VERSION ""

NS_ :

BS_:

BU_: XXX

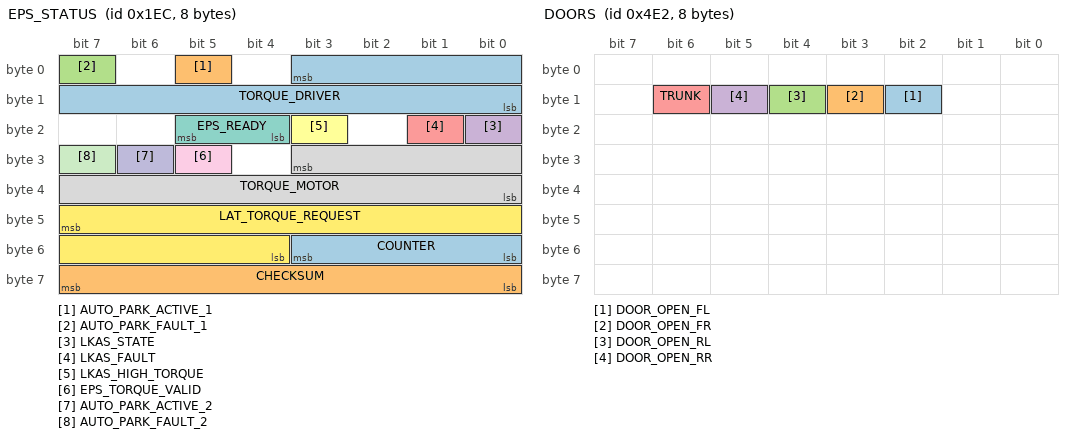
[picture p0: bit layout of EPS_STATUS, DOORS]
BO_ 492 EPS_STATUS: 8 XXX
 SG_ TORQUE_DRIVER : 3|12@0+ (1,-1024) [0|2048] "Nm" XXX
 SG_ AUTO_PARK_ACTIVE_1 : 5|1@0+ (1,0) [0|1] "" XXX
 SG_ AUTO_PARK_FAULT_1 : 7|1@0+ (1,0) [0|1] "" XXX
 SG_ LKAS_STATE : 16|1@0+ (1,0) [0|1] "" XXX
 SG_ LKAS_FAULT : 17|1@0+ (1,0) [0|1] "" XXX
 SG_ LKAS_HIGH_TORQUE : 19|1@0+ (1,0) [0|1] "" XXX
 SG_ EPS_READY : 21|2@0+ (1,0) [0|3] "" XXX
 SG_ TORQUE_MOTOR : 27|12@0+ (1,-2048) [0|1] "" XXX
 SG_ EPS_TORQUE_VALID : 29|1@0+ (1,0) [0|1] "" XXX
 SG_ AUTO_PARK_ACTIVE_2 : 30|1@0+ (1,0) [0|1] "" XXX
 SG_ AUTO_PARK_FAULT_2 : 31|1@0+ (1,0) [0|1] "" XXX
 SG_ LAT_TORQUE_REQUEST : 47|12@0+ (1,-2048) [0|4095] "" XXX
 SG_ COUNTER : 51|4@0+ (1,0) [0|15] "" XXX
 SG_ CHECKSUM : 63|8@0+ (1,0) [0|255] "" XXX

BO_ 1250 DOORS: 8 XXX
 SG_ DOOR_OPEN_FL : 10|1@0+ (1,0) [0|1] "" XXX
 SG_ DOOR_OPEN_FR : 11|1@0+ (1,0) [0|1] "" XXX
 SG_ DOOR_OPEN_RL : 12|1@0+ (1,0) [0|1] "" XXX
 SG_ DOOR_OPEN_RR : 13|1@0+ (1,0) [0|1] "" XXX
 SG_ TRUNK : 14|1@0+ (1,0) [0|1] "" XXX

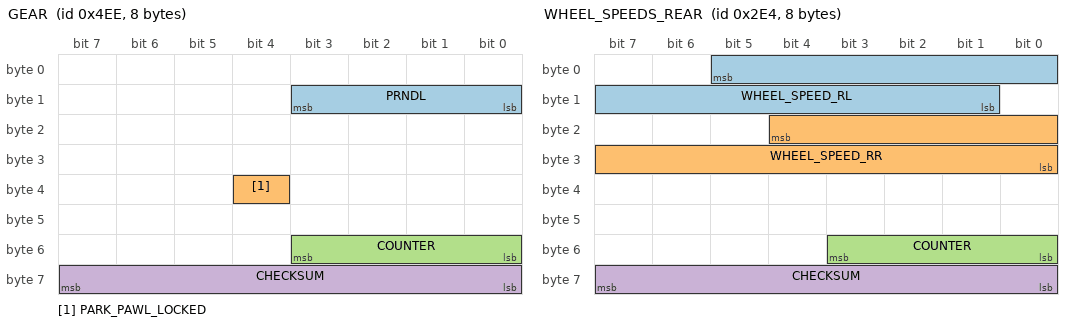
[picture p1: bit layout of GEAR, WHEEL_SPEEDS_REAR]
BO_ 1262 GEAR: 8 XXX
 SG_ PRNDL : 11|4@0+ (1,0) [0|15] "" XXX
 SG_ PARK_PAWL_LOCKED : 36|1@0+ (1,0) [0|1] "" XXX
 SG_ COUNTER : 51|4@0+ (1,0) [0|15] "" XXX
 SG_ CHECKSUM : 63|8@0+ (1,0) [0|255] "" XXX

BO_ 875 SEATBELT_STATUS: 8 XXX
 SG_ SEATBELT_DRIVER_UNLATCHED : 16|1@0+ (1,0) [0|1] "" XXX

BO_ 1264 STEERING_LEVERS: 7 XXX
 SG_ TURN_SIGNALS : 3|4@0+ (1,0) [0|15] "" XXX
 SG_ HIGH_BEAM_FLASH : 15|1@0+ (1,0) [0|1] "" XXX

BO_ 480 TRACTION_BUTTON: 8 XXX
 SG_ TRACTION_OFF : 3|1@0+ (1,0) [0|1] "" XXX

BO_ 740 WHEEL_SPEEDS_REAR: 8 XXX
 SG_ WHEEL_SPEED_RL : 5|13@0+ (0.0087,0) [0|1] "" XXX
 SG_ WHEEL_SPEED_RR : 20|13@0+ (0.0087,0) [0|1] "" XXX
 SG_ COUNTER : 51|4@0+ (1,0) [0|1] "" XXX
 SG_ CHECKSUM : 63|8@0+ (1,0) [0|1] "" XXX

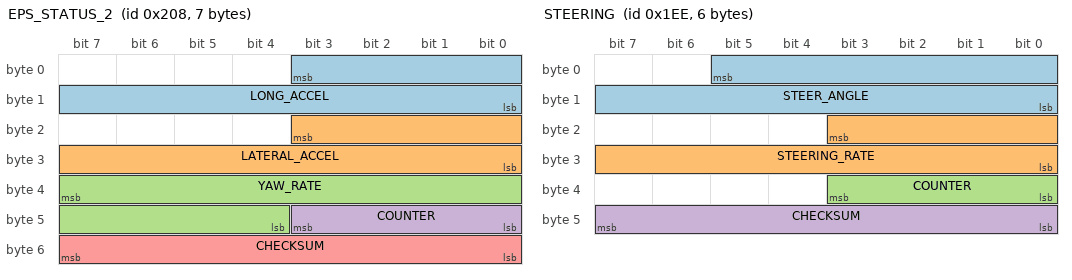
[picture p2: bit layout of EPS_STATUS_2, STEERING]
BO_ 520 EPS_STATUS_2: 7 XXX
 SG_ LONG_ACCEL : 3|12@0+ (0.00981,-20.09) [-20.09|20.08] "m/s2" XXX
 SG_ LATERAL_ACCEL : 19|12@0+ (0.00981,-20.09) [-20.09|20.08] "m/s2" XXX
 SG_ YAW_RATE : 39|12@0+ (0.0018,-3.686) [-3.686|3.685] "rad/s" XXX
 SG_ COUNTER : 43|4@0+ (1,0) [0|15] "" XXX
 SG_ CHECKSUM : 55|8@0+ (1,0) [0|255] "" XXX

BO_ 494 STEERING: 6 XXX
 SG_ STEER_ANGLE : 5|14@0+ (0.1,-720) [0|1] "deg" XXX
 SG_ STEERING_RATE : 19|12@0+ (1,-2000) [0|1] "" XXX
 SG_ COUNTER : 35|4@0+ (1,0) [0|15] "" XXX
 SG_ CHECKSUM : 47|8@0+ (1,0) [0|255] "" XXX

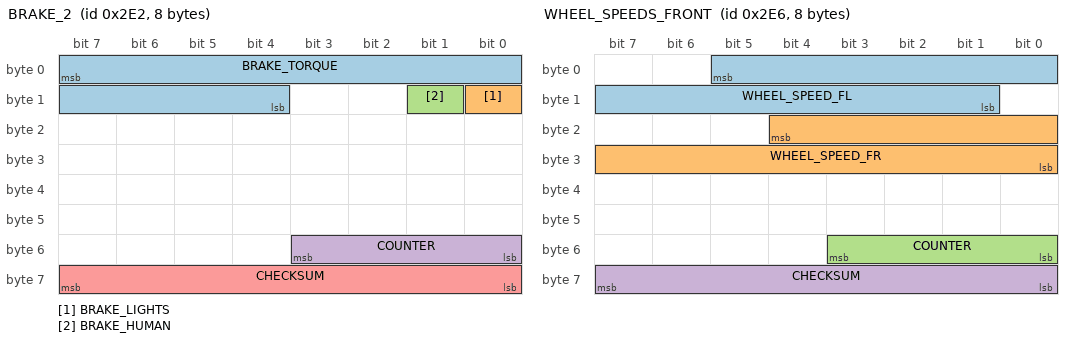
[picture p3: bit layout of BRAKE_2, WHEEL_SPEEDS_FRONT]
BO_ 738 BRAKE_2: 8 XXX
 SG_ BRAKE_TORQUE : 7|12@0+ (1,0) [0|15] "" XXX
 SG_ BRAKE_LIGHTS : 8|1@0+ (1,0) [0|1] "" XXX
 SG_ BRAKE_HUMAN : 9|1@0+ (1,0) [0|1] "" XXX
 SG_ COUNTER : 51|4@0+ (1,0) [0|1] "" XXX
 SG_ CHECKSUM : 63|8@0+ (1,0) [0|1] "" XXX

BO_ 742 WHEEL_SPEEDS_FRONT: 8 XXX
 SG_ WHEEL_SPEED_FL : 5|13@0+ (0.0087,0) [0|1] "" XXX
 SG_ WHEEL_SPEED_FR : 20|13@0+ (0.0087,0) [0|1] "" XXX
 SG_ COUNTER : 51|4@0+ (1,0) [0|1] "" XXX
 SG_ CHECKSUM : 63|8@0+ (1,0) [0|1] "" XXX

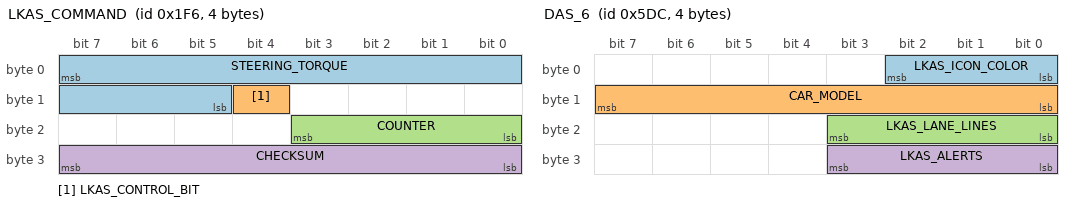
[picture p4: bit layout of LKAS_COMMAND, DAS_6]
BO_ 502 LKAS_COMMAND: 4 XXX
 SG_ STEERING_TORQUE : 7|11@0+ (1,-1024) [0|4087] "" XXX
 SG_ LKAS_CONTROL_BIT : 12|1@0+ (1,0) [0|1] "" XXX
 SG_ COUNTER : 19|4@0+ (1,0) [0|1] "" XXX
 SG_ CHECKSUM : 31|8@0+ (1,0) [0|1] "" XXX

BO_ 1498 LKAS_1: 2 XXX

BO_ 1500 DAS_6: 4 XXX
 SG_ LKAS_ICON_COLOR : 2|3@0+ (1,0) [0|7] "" XXX
 SG_ CAR_MODEL : 15|8@0+ (1,0) [0|255] "" XXX
 SG_ LKAS_LANE_LINES : 19|4@0+ (1,0) [0|15] "" XXX
 SG_ LKAS_ALERTS : 27|4@0+ (1,0) [0|1] "" XXX

BO_ 1508 LKAS_HEARTBIT: 8 XXX
 SG_ LKAS_STATUS_OK : 28|1@0+ (1,0) [0|1] "" XXX

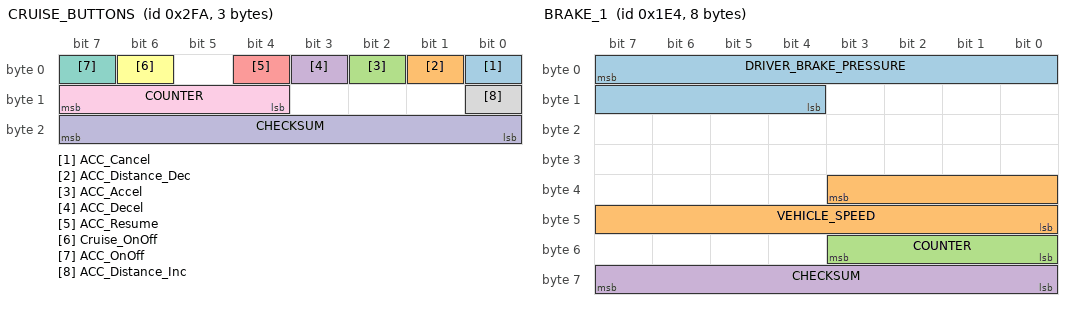
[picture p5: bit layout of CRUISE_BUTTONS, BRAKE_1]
BO_ 762 CRUISE_BUTTONS: 3 XXX
 SG_ ACC_Cancel : 0|1@0+ (1,0) [0|1] "" XXX
 SG_ ACC_Distance_Dec : 1|1@0+ (1,0) [0|1] "" XXX
 SG_ ACC_Accel : 2|1@0+ (1,0) [0|1] "" XXX
 SG_ ACC_Decel : 3|1@0+ (1,0) [0|1] "" XXX
 SG_ ACC_Resume : 4|1@0+ (1,0) [0|1] "" XXX
 SG_ Cruise_OnOff : 6|1@0+ (1,0) [0|1] "" XXX
 SG_ ACC_OnOff : 7|1@0+ (1,0) [0|1] "" XXX
 SG_ ACC_Distance_Inc : 8|1@0+ (1,0) [0|1] "" XXX
 SG_ COUNTER : 15|4@0+ (1,0) [0|1] "" XXX
 SG_ CHECKSUM : 23|8@0+ (1,0) [0|1] "" XXX

BO_ 484 BRAKE_1: 8 XXX
 SG_ DRIVER_BRAKE_PRESSURE : 7|12@0+ (1,0) [0|1] "" XXX
 SG_ VEHICLE_SPEED : 35|12@0+ (0.0174,0) [0|4095] "m/s" XXX
 SG_ COUNTER : 51|4@0+ (1,0) [0|1] "" XXX
 SG_ CHECKSUM : 63|8@0+ (1,0) [0|1] "" XXX

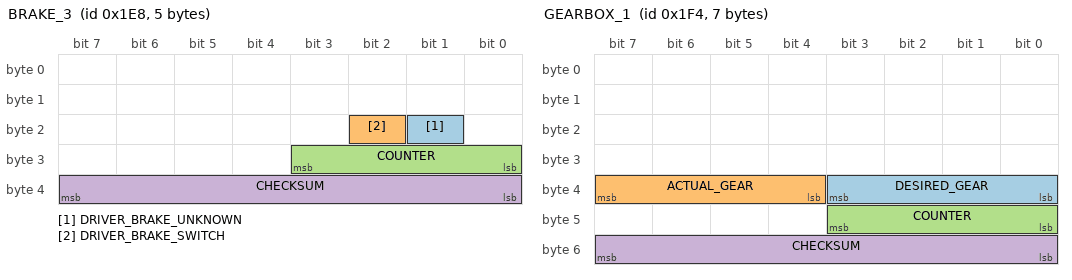
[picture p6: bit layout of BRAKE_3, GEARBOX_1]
BO_ 488 BRAKE_3: 5 XXX
 SG_ DRIVER_BRAKE_UNKNOWN : 17|1@0+ (1,0) [0|1] "" XXX
 SG_ DRIVER_BRAKE_SWITCH : 18|1@0+ (1,0) [0|1] "" XXX
 SG_ COUNTER : 27|4@0+ (1,0) [0|15] "" XXX
 SG_ CHECKSUM : 39|8@0+ (1,0) [0|255] "" XXX

BO_ 500 GEARBOX_1: 7 XXX
 SG_ DESIRED_GEAR : 35|4@0+ (1,0) [0|1] "" XXX
 SG_ ACTUAL_GEAR : 39|4@0+ (1,0) [0|1] "" XXX
 SG_ COUNTER : 43|4@0+ (1,0) [0|1] "" XXX
 SG_ CHECKSUM : 55|8@0+ (1,0) [0|1] "" XXX

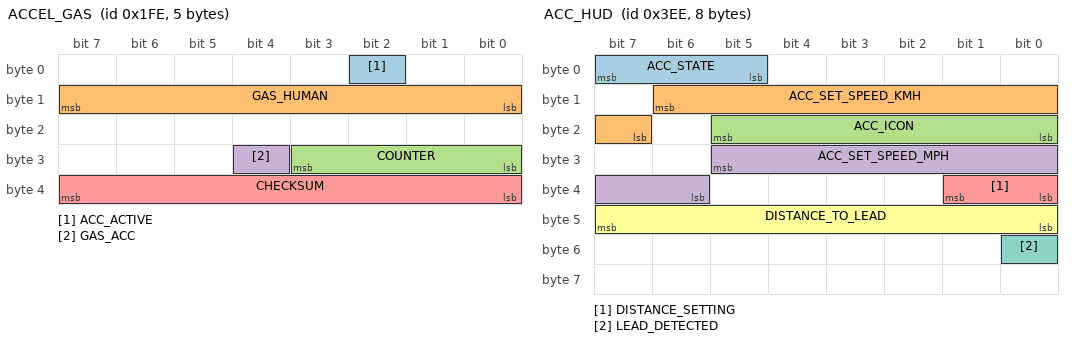
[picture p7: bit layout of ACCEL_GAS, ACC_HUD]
BO_ 510 ACCEL_GAS: 5 XXX
 SG_ ACC_ACTIVE : 2|1@0+ (1,0) [0|1] "" XXX
 SG_ GAS_HUMAN : 15|8@0+ (1,0) [0|1] "" XXX
 SG_ COUNTER : 27|4@0+ (1,0) [0|1] "" XXX
 SG_ GAS_ACC : 28|1@0+ (1,0) [0|1] "" XXX
 SG_ CHECKSUM : 39|8@0+ (1,0) [0|1] "" XXX

BO_ 490 DASHBOARD: 4 XXX
 SG_ ACC_SPEED_CONFIG_KPH : 7|8@0+ (0.1625,0) [0|1] "m/s" XXX

BO_ 1006 ACC_HUD: 8 XXX
 SG_ ACC_STATE : 7|3@0+ (1,0) [0|15] "" XXX
 SG_ ACC_SET_SPEED_KMH : 14|8@0+ (1,0) [0|255] "km/h" XXX
 SG_ ACC_ICON : 21|6@0+ (1,0) [0|63] "" XXX
 SG_ ACC_SET_SPEED_MPH : 29|8@0+ (1,0) [0|255] "mph" XXX
 SG_ DISTANCE_SETTING : 33|2@0+ (1,0) [0|3] "" XXX
 SG_ DISTANCE_TO_LEAD : 47|8@0+ (1,0) [0|255] "m" XXX
 SG_ LEAD_DETECTED : 48|1@0+ (1,0) [0|1] "" XXX

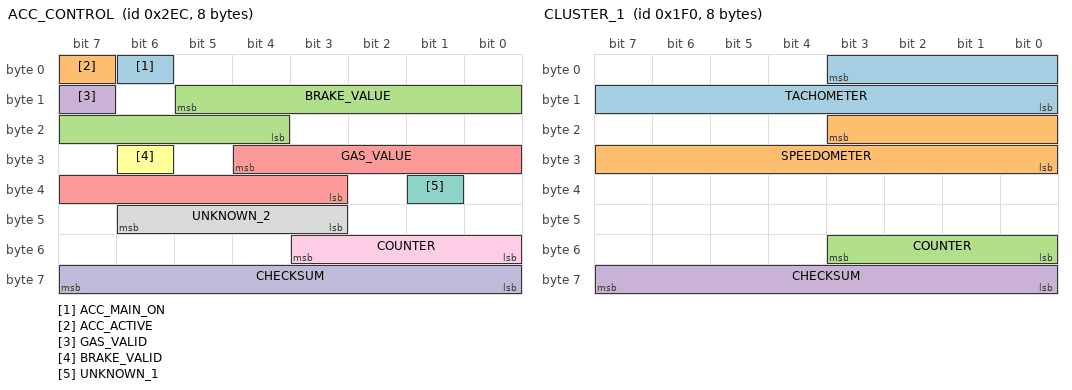
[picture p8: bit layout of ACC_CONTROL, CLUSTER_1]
BO_ 748 ACC_CONTROL: 8 XXX
 SG_ ACC_MAIN_ON : 6|1@0+ (1,0) [0|1] "" XXX
 SG_ ACC_ACTIVE : 7|1@0+ (1,0) [0|1] "" XXX
 SG_ BRAKE_VALUE : 13|10@0+ (1,0) [0|1023] "" XXX
 SG_ GAS_VALID : 15|1@0+ (1,0) [0|1] "" XXX
 SG_ GAS_VALUE : 28|10@0+ (1,0) [0|1023] "" XXX
 SG_ BRAKE_VALID : 30|1@0+ (1,0) [0|1] "" XXX
 SG_ UNKNOWN_1 : 33|1@0+ (1,0) [0|1] "" XXX
 SG_ UNKNOWN_2 : 46|4@0+ (1,0) [0|15] "" XXX
 SG_ COUNTER : 51|4@0+ (1,0) [0|15] "" XXX
 SG_ CHECKSUM : 63|8@0+ (1,0) [0|255] "" XXX

BO_ 496 CLUSTER_1: 8 XXX
 SG_ TACHOMETER : 3|12@0+ (1.024,0) [0|3] "" XXX
 SG_ SPEEDOMETER : 19|12@0+ (0.01065,0) [0|1] "m/s" XXX
 SG_ COUNTER : 51|4@0+ (1,0) [0|1] "" XXX
 SG_ CHECKSUM : 63|8@0+ (1,0) [0|1] "" XXX

BO_ 103596083 BSM_LEFT: 8 XXX
 SG_ LEFT_DETECTED : 21|1@0+ (1,0) [0|1] "" XXX

BO_ 103596084 BSM_RIGHT: 7 XXX
 SG_ RIGHT_DETECTED : 21|1@0+ (1,0) [0|1] "" XXX

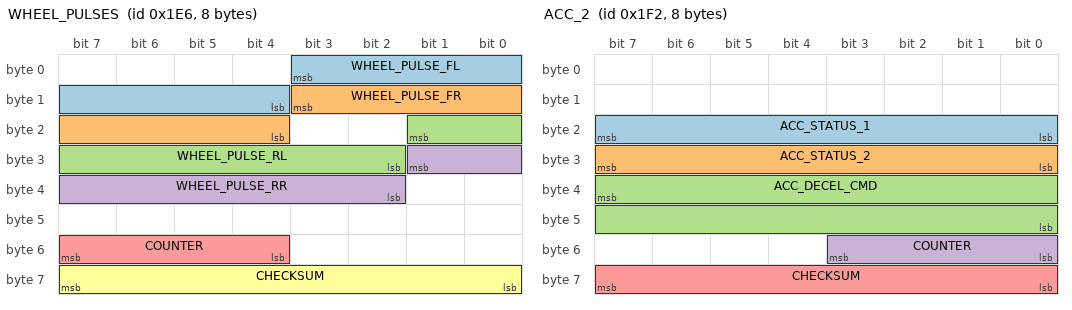
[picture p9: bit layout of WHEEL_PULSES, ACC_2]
BO_ 486 WHEEL_PULSES: 8 XXX
 SG_ WHEEL_PULSE_FL : 3|8@0+ (1,0) [0|255] "" XXX
 SG_ WHEEL_PULSE_FR : 11|8@0+ (1,0) [0|255] "" XXX
 SG_ WHEEL_PULSE_RL : 17|8@0+ (1,0) [0|255] "" XXX
 SG_ WHEEL_PULSE_RR : 25|8@0+ (1,0) [0|255] "" XXX
 SG_ COUNTER : 55|4@0+ (1,0) [0|15] "" XXX
 SG_ CHECKSUM : 63|8@0+ (1,0) [0|255] "" XXX

BO_ 498 ACC_2: 8 XXX
 SG_ ACC_STATUS_1 : 23|8@0+ (1,0) [0|255] "" XXX
 SG_ ACC_STATUS_2 : 31|8@0+ (1,0) [0|255] "" XXX
 SG_ ACC_DECEL_CMD : 39|16@0+ (1,0) [0|65535] "" XXX
 SG_ COUNTER : 51|4@0+ (1,0) [0|15] "" XXX
 SG_ CHECKSUM : 63|8@0+ (1,0) [0|255] "" XXX

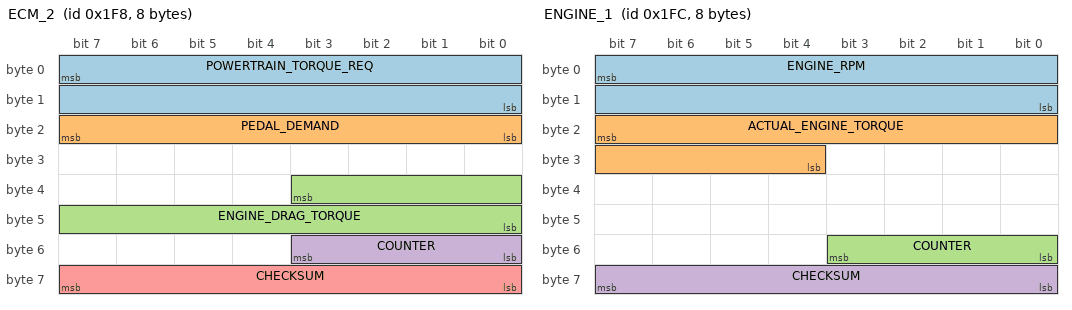
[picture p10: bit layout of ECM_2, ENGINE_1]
BO_ 504 ECM_2: 8 XXX
 SG_ POWERTRAIN_TORQUE_REQ : 7|16@0+ (1,0) [0|65535] "" XXX
 SG_ PEDAL_DEMAND : 23|8@0+ (0.4,0) [0|100] "%" XXX
 SG_ ENGINE_DRAG_TORQUE : 35|12@0+ (1,-1000) [-1000|3095] "Nm" XXX
 SG_ COUNTER : 51|4@0+ (1,0) [0|15] "" XXX
 SG_ CHECKSUM : 63|8@0+ (1,0) [0|255] "" XXX

BO_ 508 ENGINE_1: 8 XXX
 SG_ ENGINE_RPM : 7|16@0+ (1,0) [0|65535] "rpm" XXX
 SG_ ACTUAL_ENGINE_TORQUE : 23|12@0+ (1,-1000) [-1000|3095] "Nm" XXX
 SG_ COUNTER : 51|4@0+ (1,0) [0|15] "" XXX
 SG_ CHECKSUM : 63|8@0+ (1,0) [0|255] "" XXX

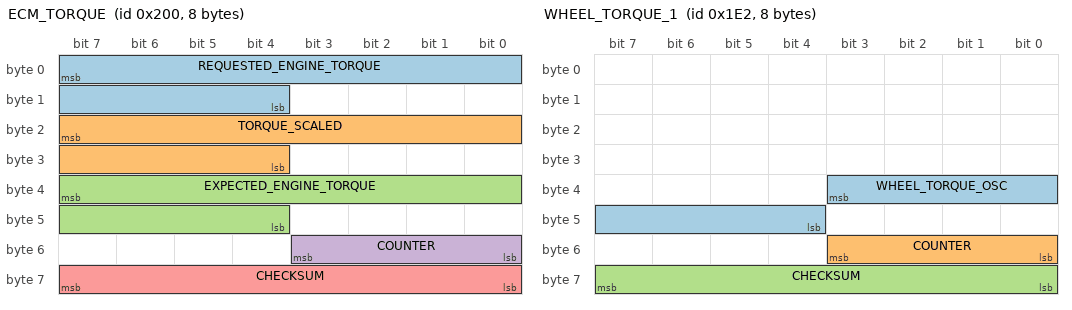
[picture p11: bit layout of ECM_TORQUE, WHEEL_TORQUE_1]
BO_ 512 ECM_TORQUE: 8 XXX
 SG_ REQUESTED_ENGINE_TORQUE : 7|12@0+ (1,-1000) [-1000|3095] "Nm" XXX
 SG_ TORQUE_SCALED : 23|12@0+ (1,-500) [-500|3595] "Nm" XXX
 SG_ EXPECTED_ENGINE_TORQUE : 39|12@0+ (1,-1000) [-1000|3095] "Nm" XXX
 SG_ COUNTER : 51|4@0+ (1,0) [0|15] "" XXX
 SG_ CHECKSUM : 63|8@0+ (1,0) [0|255] "" XXX

BO_ 482 WHEEL_TORQUE_1: 8 XXX
 SG_ WHEEL_TORQUE_OSC : 35|8@0+ (1,0) [0|255] "" XXX
 SG_ COUNTER : 51|4@0+ (1,0) [0|15] "" XXX
 SG_ CHECKSUM : 63|8@0+ (1,0) [0|255] "" XXX

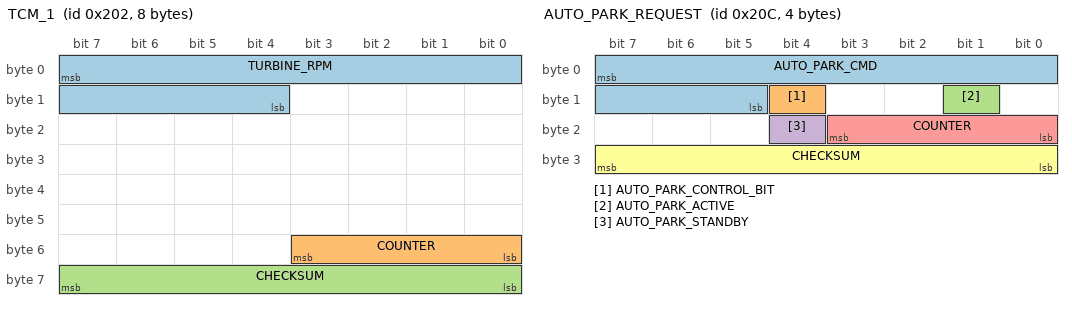
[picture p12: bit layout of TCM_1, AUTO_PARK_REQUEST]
BO_ 514 TCM_1: 8 XXX
 SG_ TURBINE_RPM : 7|12@0+ (1,0) [0|4095] "rpm" XXX
 SG_ COUNTER : 51|4@0+ (1,0) [0|15] "" XXX
 SG_ CHECKSUM : 63|8@0+ (1,0) [0|255] "" XXX

BO_ 522 SHIFTER_1: 4 XXX
 SG_ SHIFTER_TRANSITION : 15|8@0+ (1,0) [0|255] "" XXX
 SG_ SHIFTER_POSITION : 14|4@0+ (1,0) [0|15] "" XXX
 SG_ COUNTER : 19|4@0+ (1,0) [0|15] "" XXX
 SG_ CHECKSUM : 31|8@0+ (1,0) [0|255] "" XXX

BO_ 524 AUTO_PARK_REQUEST: 4 XXX
 SG_ AUTO_PARK_CMD : 7|11@0+ (1,-1024) [-1024|1023] "" XXX
 SG_ AUTO_PARK_CONTROL_BIT : 12|1@0+ (1,0) [0|1] "" XXX
 SG_ AUTO_PARK_ACTIVE : 9|1@0+ (1,0) [0|1] "" XXX
 SG_ AUTO_PARK_STANDBY : 20|1@0+ (1,0) [0|1] "" XXX
 SG_ COUNTER : 19|4@0+ (1,0) [0|15] "" XXX
 SG_ CHECKSUM : 31|8@0+ (1,0) [0|255] "" XXX

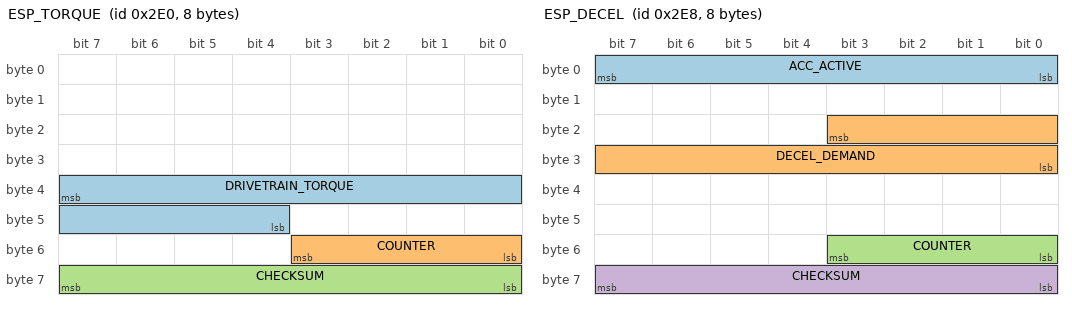
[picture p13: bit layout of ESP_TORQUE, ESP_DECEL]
BO_ 736 ESP_TORQUE: 8 XXX
 SG_ DRIVETRAIN_TORQUE : 39|12@0+ (1,0) [0|4095] "Nm" XXX
 SG_ COUNTER : 51|4@0+ (1,0) [0|15] "" XXX
 SG_ CHECKSUM : 63|8@0+ (1,0) [0|255] "" XXX

BO_ 744 ESP_DECEL: 8 XXX
 SG_ ACC_ACTIVE : 7|8@0+ (1,0) [0|255] "" XXX
 SG_ DECEL_DEMAND : 19|12@0+ (1,0) [0|4095] "" XXX
 SG_ COUNTER : 51|4@0+ (1,0) [0|15] "" XXX
 SG_ CHECKSUM : 63|8@0+ (1,0) [0|255] "" XXX

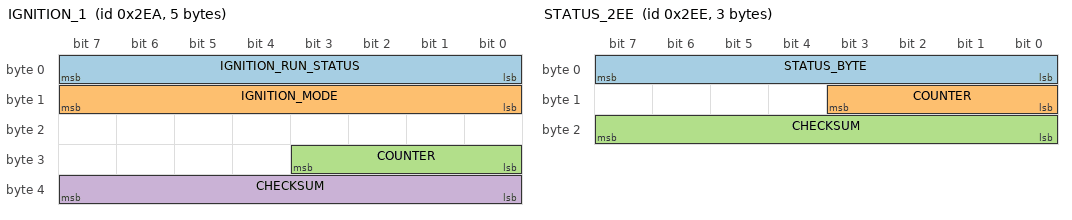
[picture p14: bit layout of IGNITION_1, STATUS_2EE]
BO_ 746 IGNITION_1: 5 XXX
 SG_ IGNITION_RUN_STATUS : 7|8@0+ (1,0) [0|255] "" XXX
 SG_ IGNITION_MODE : 15|8@0+ (1,0) [0|255] "" XXX
 SG_ COUNTER : 27|4@0+ (1,0) [0|15] "" XXX
 SG_ CHECKSUM : 39|8@0+ (1,0) [0|255] "" XXX

BO_ 750 STATUS_2EE: 3 XXX
 SG_ STATUS_BYTE : 7|8@0+ (1,0) [0|255] "" XXX
 SG_ COUNTER : 11|4@0+ (1,0) [0|15] "" XXX
 SG_ CHECKSUM : 23|8@0+ (1,0) [0|255] "" XXX

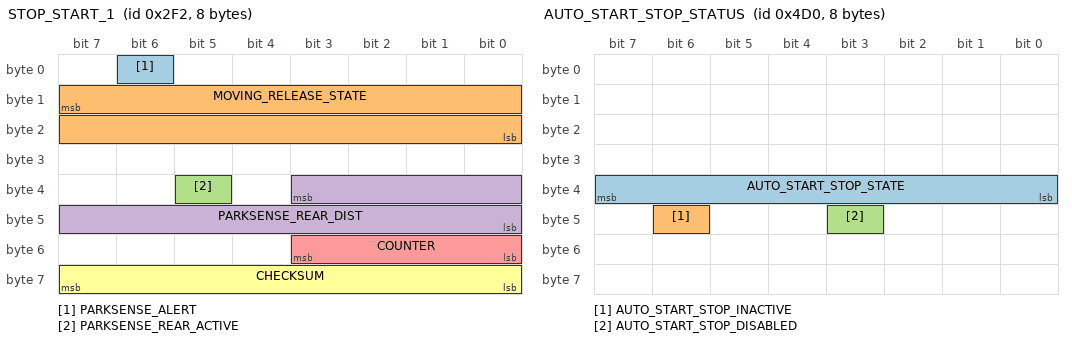
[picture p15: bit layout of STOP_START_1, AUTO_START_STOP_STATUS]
BO_ 754 STOP_START_1: 8 XXX
 SG_ PARKSENSE_ALERT : 6|1@0+ (1,0) [0|1] "" XXX
 SG_ MOVING_RELEASE_STATE : 15|16@0+ (1,0) [0|65535] "" XXX
 SG_ PARKSENSE_REAR_ACTIVE : 37|1@0+ (1,0) [0|1] "" XXX
 SG_ PARKSENSE_REAR_DIST : 35|12@0+ (1,0) [0|4095] "" XXX
 SG_ COUNTER : 51|4@0+ (1,0) [0|15] "" XXX
 SG_ CHECKSUM : 63|8@0+ (1,0) [0|255] "" XXX

BO_ 756 STOP_START_2: 5 XXX
 SG_ STOP_HOLD_STATE : 7|16@0+ (1,0) [0|65535] "" XXX

BO_ 758 IGNITION_STATE: 1 XXX
 SG_ IGNITION_STATE : 7|8@0+ (1,0) [0|255] "" XXX

BO_ 760 RFHM_START_STOP: 5 XXX
 SG_ START_STOP_BUTTON_EVENT : 7|8@0+ (1,0) [0|255] "" XXX
 SG_ KEY_FOB_VALID : 21|1@0+ (1,0) [0|1] "" XXX

BO_ 994 STATUS_3E2: 4 XXX
 SG_ ANALOG_VALUE : 23|16@0+ (1,0) [0|65535] "" XXX

BO_ 998 IGNITION_2: 5 XXX
 SG_ RUN_STATE : 31|16@0+ (1,0) [0|65535] "" XXX

BO_ 1002 ECM_3: 8 XXX
 SG_ ENGINE_LOAD_PCT : 39|8@0+ (0.4,0) [0|100] "%" XXX
 SG_ ENGINE_RPM_COARSE : 55|8@0+ (32,0) [0|8160] "rpm" XXX

BO_ 1232 AUTO_START_STOP_STATUS: 8 XXX
 SG_ AUTO_START_STOP_STATE : 39|8@0+ (1,0) [0|255] "" XXX
 SG_ AUTO_START_STOP_INACTIVE : 46|1@0+ (1,0) [0|1] "" XXX
 SG_ AUTO_START_STOP_DISABLED : 43|1@0+ (1,0) [0|1] "" XXX

BO_ 1242 ENGINE_LOAD_1: 8 XXX
 SG_ ENGINE_LOAD : 7|8@0+ (0.4,0) [0|100] "%" XXX
 SG_ THROTTLE_ACTUATOR : 31|8@0+ (0.4,0) [0|100] "%" XXX

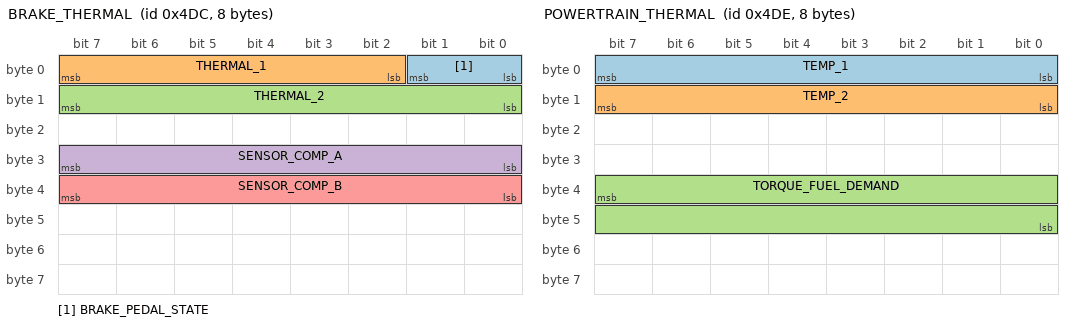
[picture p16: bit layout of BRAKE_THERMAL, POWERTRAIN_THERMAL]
BO_ 1244 BRAKE_THERMAL: 8 XXX
 SG_ BRAKE_PEDAL_STATE : 1|2@0+ (1,0) [0|3] "" XXX
 SG_ THERMAL_1 : 7|6@0+ (1,0) [0|63] "" XXX
 SG_ THERMAL_2 : 15|8@0+ (1,-40) [-40|215] "degC" XXX
 SG_ SENSOR_COMP_A : 31|8@0+ (1,0) [0|255] "" XXX
 SG_ SENSOR_COMP_B : 39|8@0+ (1,0) [0|255] "" XXX

BO_ 1246 POWERTRAIN_THERMAL: 8 XXX
 SG_ TEMP_1 : 7|8@0+ (1,-40) [-40|215] "degC" XXX
 SG_ TEMP_2 : 15|8@0+ (1,-40) [-40|215] "degC" XXX
 SG_ TORQUE_FUEL_DEMAND : 39|16@0+ (1,0) [0|65535] "" XXX

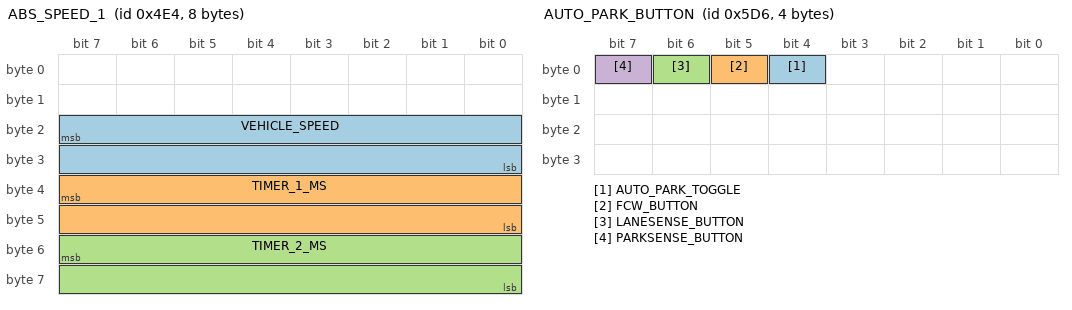
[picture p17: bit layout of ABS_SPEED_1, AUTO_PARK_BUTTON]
BO_ 1252 ABS_SPEED_1: 8 XXX
 SG_ VEHICLE_SPEED : 23|16@0+ (0.0174,0) [0|4095] "m/s" XXX
 SG_ TIMER_1_MS : 39|16@0+ (1,0) [0|65535] "ms" XXX
 SG_ TIMER_2_MS : 55|16@0+ (1,0) [0|65535] "ms" XXX

BO_ 1260 VIN: 8 XXX
 SG_ MUX M : 7|8@0+ (1,0) [0|2] "" XXX
 SG_ VIN_0_1 m0 : 15|8@0+ (1,0) [0|255] "" XXX
 SG_ VIN_0_2 m0 : 23|8@0+ (1,0) [0|255] "" XXX
 SG_ VIN_0_3 m0 : 31|8@0+ (1,0) [0|255] "" XXX
 SG_ VIN_0_4 m0 : 39|8@0+ (1,0) [0|255] "" XXX
 SG_ VIN_0_5 m0 : 47|8@0+ (1,0) [0|255] "" XXX
 SG_ VIN_0_6 m0 : 55|8@0+ (1,0) [0|255] "" XXX
 SG_ VIN_0_7 m0 : 63|8@0+ (1,0) [0|255] "" XXX
 SG_ VIN_1_1 m1 : 15|8@0+ (1,0) [0|255] "" XXX
 SG_ VIN_1_2 m1 : 23|8@0+ (1,0) [0|255] "" XXX
 SG_ VIN_1_3 m1 : 31|8@0+ (1,0) [0|255] "" XXX
 SG_ VIN_1_4 m1 : 39|8@0+ (1,0) [0|255] "" XXX
 SG_ VIN_1_5 m1 : 47|8@0+ (1,0) [0|255] "" XXX
 SG_ VIN_1_6 m1 : 55|8@0+ (1,0) [0|255] "" XXX
 SG_ VIN_1_7 m1 : 63|8@0+ (1,0) [0|255] "" XXX
 SG_ VIN_2_1 m2 : 15|8@0+ (1,0) [0|255] "" XXX
 SG_ VIN_2_2 m2 : 23|8@0+ (1,0) [0|255] "" XXX
 SG_ VIN_2_3 m2 : 31|8@0+ (1,0) [0|255] "" XXX

BO_ 1268 ABS_SPEED_2: 8 XXX
 SG_ VEHICLE_SPEED : 7|16@0+ (0.0174,0) [0|4095] "m/s" XXX

BO_ 1492 DAS_LEAD: 4 XXX
 SG_ LEAD_CAR : 23|4@0+ (1,0) [0|15] "" XXX

BO_ 1494 AUTO_PARK_BUTTON: 4 XXX
 SG_ AUTO_PARK_TOGGLE : 4|1@0+ (1,0) [0|1] "" XXX
 SG_ FCW_BUTTON : 5|1@0+ (1,0) [0|1] "" XXX
 SG_ LANESENSE_BUTTON : 6|1@0+ (1,0) [0|1] "" XXX
 SG_ PARKSENSE_BUTTON : 7|1@0+ (1,0) [0|1] "" XXX

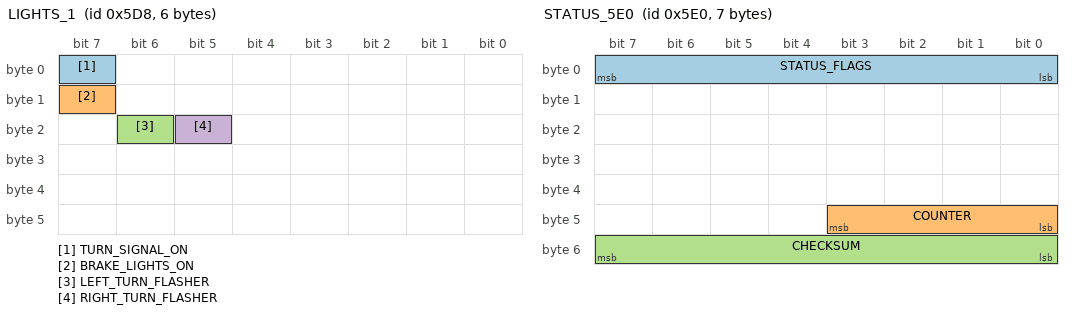
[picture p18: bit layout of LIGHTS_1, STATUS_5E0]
BO_ 1496 LIGHTS_1: 6 XXX
 SG_ TURN_SIGNAL_ON : 7|1@0+ (1,0) [0|1] "" XXX
 SG_ BRAKE_LIGHTS_ON : 15|1@0+ (1,0) [0|1] "" XXX
 SG_ LEFT_TURN_FLASHER : 22|1@0+ (1,0) [0|1] "" XXX
 SG_ RIGHT_TURN_FLASHER : 21|1@0+ (1,0) [0|1] "" XXX

BO_ 1504 STATUS_5E0: 7 XXX
 SG_ STATUS_FLAGS : 7|8@0+ (1,0) [0|255] "" XXX
 SG_ COUNTER : 43|4@0+ (1,0) [0|15] "" XXX
 SG_ CHECKSUM : 55|8@0+ (1,0) [0|255] "" XXX

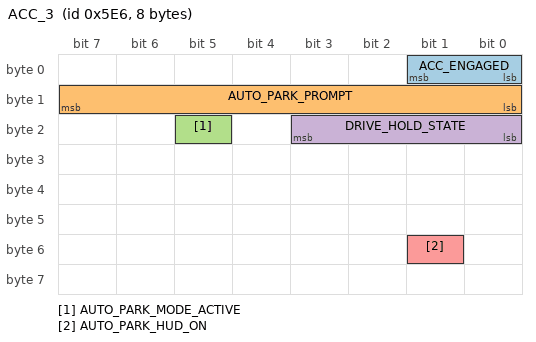
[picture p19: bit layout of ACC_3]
BO_ 1510 ACC_3: 8 XXX
 SG_ ACC_ENGAGED : 1|2@0+ (1,0) [0|3] "" XXX
 SG_ AUTO_PARK_PROMPT : 15|8@0+ (1,0) [0|255] "" XXX
 SG_ AUTO_PARK_MODE_ACTIVE : 21|1@0+ (1,0) [0|1] "" XXX
 SG_ DRIVE_HOLD_STATE : 19|4@0+ (1,0) [0|15] "" XXX
 SG_ AUTO_PARK_HUD_ON : 49|1@0+ (1,0) [0|1] "" XXX

BO_ 1625 FUEL_LEVEL: 4 XXX
 SG_ FUEL_LEVEL_RAW : 7|16@0+ (1,0) [0|65535] "" XXX

BO_ 1627 PARK_SHUTDOWN: 1 XXX
 SG_ PARK_SHUTDOWN_STATUS : 7|8@0+ (1,0) [0|255] "" XXX

BO_ 1752 RADAR_STATUS_1: 2 XXX
 SG_ ACC_ENGAGED : 0|1@0+ (1,0) [0|1] "" XXX
 SG_ ACC_FCW_FAULT : 14|1@0+ (1,0) [0|1] "" XXX

BO_ 1756 RADAR_STATUS_2: 4 XXX
 SG_ RADAR_STATE : 7|8@0+ (1,0) [0|255] "" XXX

BO_ 1992 IPC_CLOCK: 8 XXX
 SG_ SECONDS_COUNTER : 55|16@0+ (0.1,0) [0|6553.5] "s" XXX

BO_ 1996 AUTO_START_STOP_BUTTON: 2 XXX
 SG_ AUTO_START_STOP_PRESSED : 13|1@0+ (1,0) [0|1] "" XXX
 SG_ AUTO_START_STOP_PRESSED_ALT : 10|1@0+ (1,0) [0|1] "" XXX

BO_ 1999 ODOMETER: 5 XXX
 SG_ ODOMETER_KM : 7|24@0+ (1,0) [0|16777215] "km" XXX

CM_ SG_ 1250 TRUNK "1 = open, 0 = closed";
CM_ SG_ 1250 DOOR_OPEN_FL "1 = open, 0 = closed";
CM_ SG_ 1250 DOOR_OPEN_FR "1 = open, 0 = closed";
CM_ SG_ 1250 DOOR_OPEN_RL "1 = open, 0 = closed";
CM_ SG_ 1250 DOOR_OPEN_RR "1 = open, 0 = closed";
CM_ SG_ 1262 PRNDL "1 = park, 2 = reverse, 3 = neutral, 4 = drive, 5 = sport (snicker... sport)";
CM_ SG_ 875 SEATBELT_DRIVER_UNLATCHED "1 = unlatched, 0 = safety first";
CM_ SG_ 1264 TURN_SIGNALS "0 = off, 1 = left blinker, 2 = right blinker";
CM_ SG_ 480 TRACTION_OFF "0 = TCS on, 1 = TCS off (light on dash ON)";
CM_ SG_ 1500 LKAS_LANE_LINES "0x01 transparent lines, 0x02 left white, 0x03 right white, 0x04 left yellow with car on top, 0x05 left yellow with car on top, 0x06 both white, 0x07 left yellow, 0x08 left yellow right white, 0x09 right yellow, 0x0a right yellow left white, 0x0b left yellow with car on top right white, 0x0c right yellow with car on top left white, (0x00, 0x0d, 0x0e, 0x0f) null";
CM_ SG_ 1492 LEAD_CAR "lead car present = 4, no car = 2 ";
CM_ SG_ 498 ACC_STATUS_2 "1 no ACC, 3 icpno ";
CM_ SG_ 498 ACC_STATUS_1 "0x00 = acc off, 0x03 = acc on, green, 0x02 acc on, white";
CM_ SG_ 1006 ACC_STATE "0 = ACC off, 6 = ACC active (white), 8 = ACC engaged (green)";
CM_ SG_ 502 LKAS_STATE "2 = active (green), 1 = error";
CM_ SG_ 1006 ACC_SET_SPEED_KMH "Minimum selectable ACC set speed is 32 km/h (20 mph) on 2019 Jeep Cherokee";
CM_ SG_ 492 AUTO_PARK_FAULT_1 "1 when PAM 0x20C standby/control message is missing or Auto-Park faulted";
CM_ SG_ 492 EPS_READY "EPS status nibble bits: 3 = normal/ready, 0 = faulted (missing PAM 0x20C)";
CM_ SG_ 492 EPS_TORQUE_VALID "1 when EPS steering torque output is normal/valid";
CM_ SG_ 492 AUTO_PARK_FAULT_2 "1 when PAM 0x20C standby/control message is missing or Auto-Park faulted";
CM_ SG_ 1262 PARK_PAWL_LOCKED "1 when Park pawl is engaged, 0 in R/N/D";
CM_ SG_ 522 SHIFTER_TRANSITION "Raw byte 1 of 50 Hz ESM shifter status (0x08=P, 0x10=R, 0x18=N, 0x20=D, 0x00=transition)";
CM_ SG_ 522 SHIFTER_POSITION "50 Hz ESM shifter position: 1 = P (0x08), 2 = R (0x10), 3 = N (0x18), 4 = D (0x20), 0 = shifting transition";
CM_ SG_ 746 IGNITION_RUN_STATUS "0x84 ignition RUN, 0x83/0x80 ignition OFF shutdown";
CM_ SG_ 754 MOVING_RELEASE_STATE "Transmitted by PAM module alongside 0x20C; 0xFFFF moving/released, 0x00F0 low-speed braking/stop hold";
CM_ SG_ 756 STOP_HOLD_STATE "Transmitted by PAM module alongside 0x20C; 0x1FFF moving/released, 0x8001 low-speed braking/stop hold";
CM_ SG_ 758 IGNITION_STATE "0x01 OFF, 0x2E ACC, 0x32 RUN, 0x36 START";
CM_ SG_ 760 START_STOP_BUTTON_EVENT "RFHM (0xC7) Start/Stop button event code on press/hold; 0 when idle";
CM_ SG_ 760 KEY_FOB_VALID "1 when key fob is detected valid during Start/Stop button press";
CM_ SG_ 524 AUTO_PARK_CMD "Signed steering torque command from PAM during active self-parking (offset -1024, r=+0.975 with EPS_STATUS.TORQUE_MOTOR)";
CM_ SG_ 524 AUTO_PARK_CONTROL_BIT "1 when PAM is actively steering the wheel (100 Hz mode)";
CM_ SG_ 524 AUTO_PARK_ACTIVE "1 during active self-parking torque control";
CM_ SG_ 524 AUTO_PARK_STANDBY "1 from ParkSense button press while searching / parking / awaiting shift";
CM_ SG_ 1232 AUTO_START_STOP_STATE "Auto Start/Stop (ESS) state: 0x04 ready/enabled, 0x03 disabled via center-stack button, 0x07 unavailable/not ready";
CM_ SG_ 1232 AUTO_START_STOP_INACTIVE "1 when Auto Start/Stop (ESS) is off or unavailable (byte 5 bit 6)";
CM_ SG_ 1232 AUTO_START_STOP_DISABLED "1 when Auto Start/Stop (ESS) is explicitly disabled via center-stack button (byte 5 bit 3)";
CM_ SG_ 1244 BRAKE_PEDAL_STATE "0 = released, 1 = brake pedal pressed";
CM_ SG_ 1494 AUTO_PARK_TOGGLE "Pulses 1 when ParkSense self-parking button is pressed";
CM_ SG_ 1494 FCW_BUTTON "Pulses 1 when Forward Collision Warning (FCW) center-stack button is pressed";
CM_ SG_ 1494 LANESENSE_BUTTON "Pulses 1 when LaneSense center-stack button is pressed";
CM_ SG_ 1494 PARKSENSE_BUTTON "Pulses 1 when ParkSense off/on center-stack button is pressed";
CM_ SG_ 1496 LEFT_TURN_FLASHER "1 Hz exterior left turn signal bulb flasher state";
CM_ SG_ 1496 RIGHT_TURN_FLASHER "1 Hz exterior right turn signal bulb flasher state";
CM_ SG_ 1510 ACC_ENGAGED "Transmitted by PAM module alongside 0x20C (stops if PAM is offline)";
CM_ SG_ 1510 AUTO_PARK_PROMPT "ParkSense UI guidance/prompt code (0x02 searching/forward, 0x3c/0x44 reverse/spot, 0x48 pull forward, 0x1e stop/shift)";
CM_ SG_ 1510 DRIVE_HOLD_STATE "0x06 moving/released (also bit 2 = 1 when ParkSense is turned off via 0x5D6 PARKSENSE_BUTTON), 0x02 low-speed braking/stop hold";
CM_ SG_ 1752 ACC_FCW_FAULT "1 when FCW is disabled via center-stack button (0x5D6 FCW_BUTTON) or during ACC/FCW fault (ACC_ICON == 0x3A)";
CM_ SG_ 1996 AUTO_START_STOP_PRESSED "Pulses 1 when Auto Start/Stop (ESS) center-stack button is pressed (0x7CC 8002 -> 8026 -> 8002)";
CM_ SG_ 1996 AUTO_START_STOP_PRESSED_ALT "Secondary bit that pulses 1 alongside AUTO_START_STOP_PRESSED on 0x7CC";
VAL_ 522 SHIFTER_POSITION 0 "TRANSITION" 1 "P" 2 "R" 3 "N" 4 "D";
VAL_ 758 IGNITION_STATE 1 "OFF" 46 "ACC" 50 "RUN" 54 "START";
VAL_ 1262 PRNDL 1 "P" 2 "R" 3 "N" 4 "D" 5 "S";
